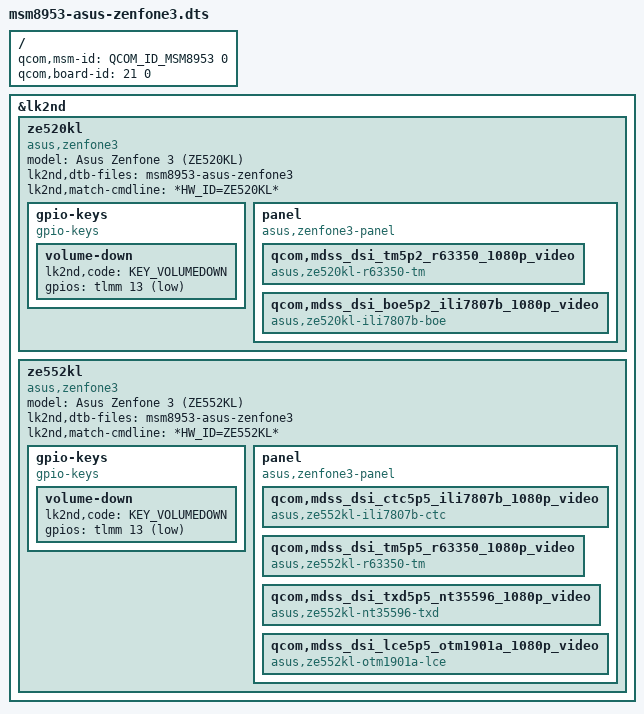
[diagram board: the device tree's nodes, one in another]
// SPDX-License-Identifier: BSD-3-Clause

/dts-v1/;

#include <skeleton64.dtsi>
#include <lk2nd.dtsi>

/ {
	qcom,msm-id = <QCOM_ID_MSM8953 0>;
	qcom,board-id = <21 0>;
};

&lk2nd {
	ze520kl {
		model = "Asus Zenfone 3 (ZE520KL)";
		compatible = "asus,zenfone3", "asus,ze520kl";
		lk2nd,dtb-files = "msm8953-asus-zenfone3";
		lk2nd,match-cmdline = "*HW_ID=ZE520KL*";

		gpio-keys {
			compatible = "gpio-keys";

			volume-down {
				lk2nd,code = <KEY_VOLUMEDOWN>;
				gpios = <&tlmm 13 (GPIO_ACTIVE_LOW | GPIO_PULL_UP)>;
			};
		};

		panel {
			compatible = "asus,zenfone3-panel", "lk2nd,panel";

			qcom,mdss_dsi_tm5p2_r63350_1080p_video {
				compatible = "asus,ze520kl-r63350-tm";
			};

			qcom,mdss_dsi_boe5p2_ili7807b_1080p_video {
				compatible = "asus,ze520kl-ili7807b-boe";
			};
		};
	};

	ze552kl {
		model = "Asus Zenfone 3 (ZE552KL)";
		compatible = "asus,zenfone3", "asus,ze552kl";
		lk2nd,dtb-files = "msm8953-asus-zenfone3";
		lk2nd,match-cmdline = "*HW_ID=ZE552KL*";

		gpio-keys {
			compatible = "gpio-keys";

			volume-down {
				lk2nd,code = <KEY_VOLUMEDOWN>;
				gpios = <&tlmm 13 (GPIO_ACTIVE_LOW | GPIO_PULL_UP)>;
			};
		};

		panel {
			compatible = "asus,zenfone3-panel", "lk2nd,panel";

			qcom,mdss_dsi_ctc5p5_ili7807b_1080p_video {
				compatible = "asus,ze552kl-ili7807b-ctc";
			};

			qcom,mdss_dsi_tm5p5_r63350_1080p_video {
				compatible = "asus,ze552kl-r63350-tm";
			};

			qcom,mdss_dsi_txd5p5_nt35596_1080p_video {
				compatible = "asus,ze552kl-nt35596-txd";
			};

			qcom,mdss_dsi_lce5p5_otm1901a_1080p_video {
				compatible = "asus,ze552kl-otm1901a-lce";
			};
		};
	};
};
